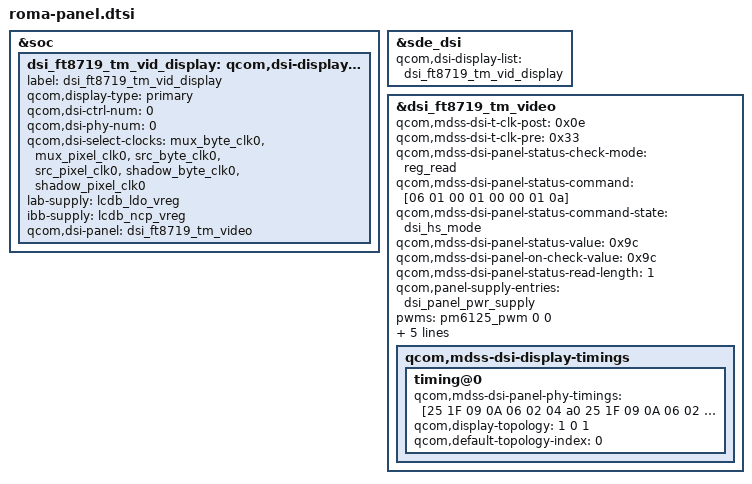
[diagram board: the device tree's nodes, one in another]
/*
 * Copyright (c) 2019, The Linux Foundation. All rights reserved.
 *
 * This program is free software; you can redistribute it and/or modify
 * it under the terms of the GNU General Public License version 2 and
 * only version 2 as published by the Free Software Foundation.
 *
 * This program is distributed in the hope that it will be useful,
 * but WITHOUT ANY WARRANTY; without even the implied warranty of
 * MERCHANTABILITY or FITNESS FOR A PARTICULAR PURPOSE.  See the
 * GNU General Public License for more details.
 */

#include "dsi-panel-ft8719-tm-fhd-video.dtsi"



&soc {
	dsi_ft8719_tm_vid_display: qcom,dsi-display@4 {
		label = "dsi_ft8719_tm_vid_display";
		qcom,display-type = "primary";

		qcom,dsi-ctrl-num = <0>;
		qcom,dsi-phy-num = <0>;
		qcom,dsi-select-clocks = "mux_byte_clk0", "mux_pixel_clk0",
			"src_byte_clk0", "src_pixel_clk0",
			"shadow_byte_clk0", "shadow_pixel_clk0";
		lab-supply = <&lcdb_ldo_vreg>;
		ibb-supply = <&lcdb_ncp_vreg>;
		qcom,dsi-panel = <&dsi_ft8719_tm_video>;
	};
};

&sde_dsi {
	qcom,dsi-display-list = <
				  &dsi_ft8719_tm_vid_display>;
        /delete-property/ qcom,platform-te-gpio;
};


&dsi_ft8719_tm_video {
	qcom,mdss-dsi-t-clk-post = <0x0e>;
	qcom,mdss-dsi-t-clk-pre = <0x33>;
	/*qcom,dsi-supported-dfps-list = <60 55 48>;
	qcom,mdss-dsi-pan-enable-dynamic-fps;
	qcom,mdss-dsi-pan-fps-update =
		"dfps_immediate_porch_mode_vfp";*/
	qcom,mdss-dsi-panel-status-check-mode = "reg_read";
	qcom,mdss-dsi-panel-status-command = [06 01 00 01 00 00 01 0a];
	qcom,mdss-dsi-panel-status-command-state = "dsi_hs_mode";
	qcom,mdss-dsi-panel-status-value = <0x9c>;
	qcom,mdss-dsi-panel-on-check-value = <0x9c>;
	qcom,mdss-dsi-panel-status-read-length = <1>;
	//qcom,dsi-dyn-clk-enable;
	//qcom,dsi-dyn-clk-list =
	//	<1005903360 989138304 993329568 997520832 1001712096>;
	qcom,mdss-dsi-display-timings {
		timing@0{
			qcom,mdss-dsi-panel-phy-timings =
				[25 1F 09 0A 06 02 04 a0
				25 1F 09 0A 06 02 04 a0
				25 1F 09 0A 06 02 04 a0
				25 1F 09 0A 06 02 04 a0
				25 1D 08 0A 06 03 04 a0];

			qcom,display-topology = <1 0 1>;
			qcom,default-topology-index = <0>;
		};
	};
};

&dsi_ft8719_tm_video {
	qcom,panel-supply-entries = <&dsi_panel_pwr_supply>;
	pwms = <&pm6125_pwm 0 0>;
	qcom,mdss-dsi-bl-pmic-control-type = "bl_ctrl_dcs";
	qcom,mdss-dsi-bl-min-level = <1>;
	qcom,mdss-dsi-bl-max-level = <4095>;
	qcom,platform-reset-gpio = <&tlmm 90 0>;
};


